# N570F064_v4_2 register map
File version: 1.0
Registers are 32-bit, read-write, reset 0x0 unless marked. A register's access mark holds for its fields unless they carry their own. Offsets are from the block's base; [hi:lo] are bit positions.

## PDMA_CH0 — PDMA Register Map
Base 0x50009000
Same registers: PDMA_CH1 0x50009100
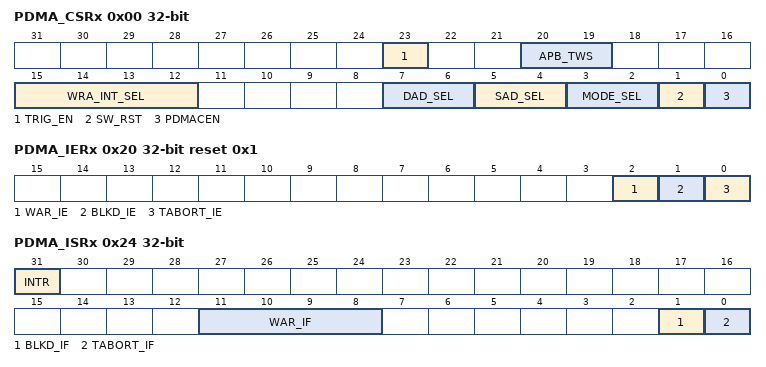
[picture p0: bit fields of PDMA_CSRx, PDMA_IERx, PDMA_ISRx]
0x00 PDMA_CSRx — PDMA Channel x Control Register
  [23] TRIG_EN — Trigger Enable - Start a PDMA operation. Note: When PDMA transfer completed, this bit will be cleared automatically. If a bus error occurs, all PDMA transfer will be stopped. Software must reset PDMA channel, and then trigger again.
    0=Write: no effect. Read: Idle/Finished; 1=Enable PDMA data read or write transfer
  [20:19] APB_TWS — Peripheral Transfer Width Select. This parameter determines the data width to be transferred each PDMA transfer operation. Note: This field is meaningful only when MODE_SEL is IP to Memory mode (APB-to-Memory) or Memory to IP mode (Memory-to-APB).
    0=One word (32 bits) is transferred for every PDMA operation; 1=One byte (8 bits) is transferred for every PDMA operation; 2=One half-word (16 bits) is transferred for every PDMA operation
  [15:12] WRA_INT_SEL — Wrap Interrupt Select x1x1: Both half and w interrupts generated.
  [7:6] DAD_SEL — Destination Address Select. This parameter determines the behavior of the current destination address register with each PDMA transfer. It can either be fixed, incremented or wrapped.
    0=Transfer Destination Address is incremented; 2=Transfer Destination Address is fixed (Used when data transferred from multiple addresses to a single destination such as peripheral FIFO input); 3=Transfer Destination Address is wrapped. When CBCR (Current Byte Count) equals zero, the CDAR (Current Destination Address) and CBCR registers will be reloaded from the DAR (Destination Address) and BCR (Byte Count) registers automatically and PDMA will start another transfer. Cycle continues until software sets PDMA_EN=0. When PDMA_EN is disabled, the PDMA will complete the active transfer but the remaining data in the SBUF will not be transferred to the destination address
  [5:4] SAD_SEL — Source Address Select. This parameter determines the behavior of the current source address register with each PDMA transfer. It can either be fixed, incremented or wrapped.
    0=Transfer Source address is incremented; 2=Transfer Source address is fixed; 3=Transfer Source address is wrapped. When CBCR (Current Byte Count) equals zero, the CSAR (Current Source Address) and CBCR registers will be reloaded from the SAR (Source Address) and BCR (Byte Count) registers automatically and PDMA will start another transfer. Cycle continues until software sets PDMA_EN=0. When PDMA_EN is disabled, the PDMA will complete the active transfer but the remaining data in the SBUF will not be transferred to the destination address
  [3:2] MODE_SEL — PDMA Mode Select. This parameter selects to transfer direction of the PDMA channel. Possible values are:
    0=Memory to Memory mode (SRAM-to-SRAM); 1=IP to Memory mode (APB-to-SRAM); 2=Memory to IP mode (SRAM-to-APB)
  [1] SW_RST — Software Engine Reset
    0=Writing 0 to this bit has no effect; 1=Writing 1 to this bit will reset the internal state machine and pointers. The contents of the control register will not be cleared. This bit will auto clear after a few clock cycles
  [0] PDMACEN — PDMA Channel Enable. Setting this bit to 1 enables PDMA's operation. If this bit is cleared, PDMA will ignore all PDMA request and force Bus Master into IDLE state. Note: SW_RST will clear this bit.
0x04 PDMA_SARx — PDMA Channel x Source Address Register
  [31:0] SAR — PDMA Transfer Source Address Register. This register holds the initial Source Address of PDMA transfer. Note: The source address must be word aligned.
0x08 PDMA_DARx — PDMA Channel x Destination Address Register
  [31:0] DAR — PDMA Transfer Destination Address Register. This register holds the initial Destination Address of PDMA transfer. Note: The destination address must be word aligned.
0x0C PDMA_BCRx — PDMA Channel x Transfer Byte Count Register
  [15:0] BCR — PDMA Transfer Byte Count Register. This register controls the transfer byte count of PDMA. Maximum value is 0xFFFF.
0x10 PDMA_POINTx ro — PDMA Channel x Internal Buffer Pointer Register
  [3:0] POINT — PDMA Internal Buffer Pointer Register (Read Only). A PDMA transaction consists of two stages, a read from the source address and a write to the destination address. Internally this data is buffered in a 32bit register. If transaction width between the read and write transactions are different, this register tracks which byte/half-word of the internal buffer is being processed by the current transaction.
0x14 PDMA_CSARx ro — PDMA Channel x Current Source Address Register
  [31:0] CSAR — PDMA Current Source Address Register (Read Only). This register returns the source address from which the PDMA transfer is occurring. This register is loaded from SAR when PDMA is triggered or when a wraparound occurs.
0x18 PDMA_CDARx ro — PDMA Channel x Current Destination Address Register
  [31:0] CDAR — PDMA Current Destination Address Register (Read Only). This register returns the destination address to which the PDMA transfer is occurring. This register is loaded from DAR when PDMA is triggered or when a wraparound occurs.
0x1C PDMA_CBCRx ro — PDMA Channel x Current Transfer Byte Count Register
  [15:0] CBCR — PDMA Current Byte Count Register (Read Only). This field indicates the current remaining byte count of PDMA transfer. This register is initialized with BCR register when PDMA is triggered or when a wraparound occurs
0x20 PDMA_IERx reset 0x1 — PDMA Channel x Interrupt Enable Register
  [2] WAR_IE — Wraparound Interrupt Enable. If enabled, and channel source or destination address is in wraparound mode, the PDMA controller will generate a WRAP interrupt to the CPU according to the setting of CSR.WRA_INT_SEL. This can be interrupts when the transaction has finished and has wrapped around and/or when the transaction is half way in progress. This allows the efficient implementation of circular buffers for DMA.
    0=Disable Wraparound PDMA interrupt generation; 1=Enable Wraparound interrupt generation
  [1] BLKD_IE — PDMA Transfer Done Interrupt Enable. If enabled, the PDMA controller will generate and interrupt to the CPU when the requested PDMA transfer is complete.
    0=Disable PDMA transfer done interrupt generation; 1=Enable PDMA transfer done interrupt generation
  [0] TABORT_IE — PDMA Read/Write Target Abort Interrupt Enable. If enabled, the PDMA controller will generate and interrupt to the CPU whenever a PDMA transaction is aborted due to an error. If a transfer is aborted, PDMA channel must be reset to resume DMA operation.
    0=Disable PDMA transfer target abort interrupt generation; 1=Enable PDMA transfer target abort interrupt generation
0x24 PDMA_ISRx — PDMA Channel x Interrupt Status Register
  [31] INTR ro — Interrupt Pin Status (Read Only). This bit is the Interrupt pin status of PDMA channel.
  [11:8] WAR_IF — Wrap around transfer byte count interrupt flag. These flags are set whenever the conditions for a wraparound interrupt (complete or half complete) are met. They are cleared by writing one to the bits.
    1=Current transfer finished flag (CBCR==0); 4=Current transfer half complete flag (CBCR==BCR/2)
  [1] BLKD_IF — Block Transfer Done Interrupt Flag. This bit indicates that PDMA block transfer complete interrupt has been generated. It is cleared by writing 1 to the bit.
    0=Transfer ongoing or Idle; 1=Transfer Complete
  [0] TABORT_IF — PDMA Read/Write Target Abort Interrupt Flag. This flag indicates a Target Abort interrupt condition has occurred. This condition can happen if attempt is made to read/write from invalid or non-existent memory space. It occurs when PDMA controller receives a bus error from AHB master. Upon occurrence PDMA will stop transfer and go to idle state. To resume, software must reset PDMA channel and initiate transfer again. NOTE: This bit is cleared by writing 1 to itself.
    0=No bus ERROR response received; 1=Bus ERROR response received
